AUTOSAR XML (schema 4-0-3)
standard types defined: Boolean, UInt32
package /AUTOSAR_Platform/DataConstrs
  range DC_Boolean: raw 0..1
package /PATAC/MSM/ComponentTypes
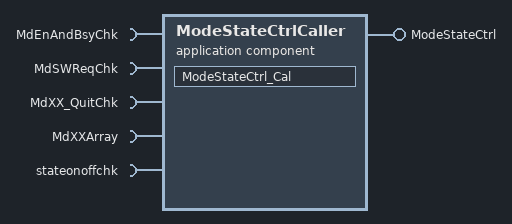
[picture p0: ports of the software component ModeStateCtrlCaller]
  application sw component type ModeStateCtrlCaller
    provide port ModeStateCtrl: server-com-spec{operation=ModeStateCtrl/Cal, queue-length=1}, provided-interface=ModeStateCtrl
    5 x require port:
      MdEnAndBsyChk: client-com-spec=MdEnAndBsyChk/Cal, required-interface=MdEnAndBsyChk
      MdSWReqChk: client-com-spec=MdSWReqChk/Cal, required-interface=MdSWReqChk
      MdXX_QuitChk: client-com-spec=MdXX_QuitChk/Cal, required-interface=MdXX_QuitChk
      MdXXArray: client-com-spec=MdXXArray/Cal, required-interface=MdXXArray
      stateonoffchk: client-com-spec=stateonoffchk/Cal, required-interface=stateonoffchk
    behavior ModeStateCtrlCaller_InternalBehavior
      operation invoked event OIT_ModeStateCtrl_Cal_ModeStateCtrl_Cal: start-on-event=ModeStateCtrl_Cal, operation=ModeStateCtrl.Cal
      runnable ModeStateCtrl_Cal
        5 x sync call, all with timeout=0:
          SC_MdEnAndBsyChk_Cal: operation=MdEnAndBsyChk.Cal
          SC_MdSWReqChk_Cal: operation=MdSWReqChk.Cal
          SC_MdXX_QuitChk_Cal: operation=MdXX_QuitChk.Cal
          SC_MdXXArray_Cal: operation=MdXXArray.Cal
          SC_stateonoffchk_Cal: operation=stateonoffchk.Cal
  swc implementation ModeStateCtrlCaller_Implementation: behavior=ModeStateCtrlCaller_InternalBehavior
    code-descriptors:
      code Default: artifact-descriptors=autosar-engineering-object={short-label=Default, category=SWSRC}
package /PATAC/MSM/ModeAdjust/PortInterface
  6 x client server interface:
    MdEnAndBsyChk
      operation Cal
        arg modestate32: type=UInt32, direction=OUT, server-argument-impl-policy=USE-ARGUMENT-TYPE
    MdSWReqChk
      operation Cal
        arg modestate32: type=UInt32, direction=IN, server-argument-impl-policy=USE-ARGUMENT-TYPE
    MdXX_QuitChk
      operation Cal
    MdXXArray
      operation Cal
    ModeStateCtrl
      operation Cal
    stateonoffchk
      operation Cal
        arg modestate32: type=UInt32, direction=IN, server-argument-impl-policy=USE-ARGUMENT-TYPE
        arg modestateon: type=Boolean, direction=OUT, server-argument-impl-policy=USE-ARGUMENT-TYPE
